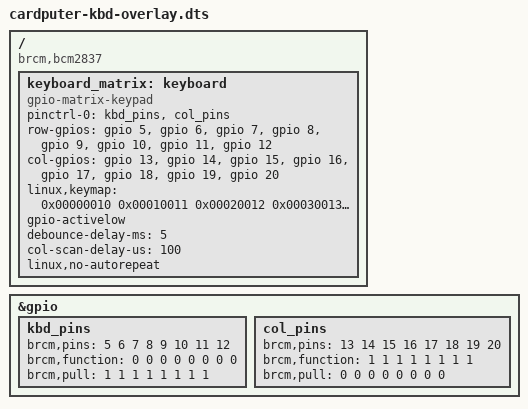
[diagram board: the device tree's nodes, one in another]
// Cardputer Zero 46-Key Matrix Keyboard Overlay
// NOTE: GPIO pin assignments are PLACEHOLDERS pending M5Stack pinout
/dts-v1/;
/plugin/;

/ {
    compatible = "brcm,bcm2837";

    fragment@0 {
        target = <&gpio>;
        __overlay__ {
            kbd_pins: kbd_pins {
                brcm,pins = <5 6 7 8 9 10 11 12>;  // PLACEHOLDER: row pins
                brcm,function = <0 0 0 0 0 0 0 0>; // input
                brcm,pull = <1 1 1 1 1 1 1 1>;     // pull-up
            };
            col_pins: col_pins {
                brcm,pins = <13 14 15 16 17 18 19 20>; // PLACEHOLDER: col pins
                brcm,function = <1 1 1 1 1 1 1 1>;     // output
                brcm,pull = <0 0 0 0 0 0 0 0>;         // no pull
            };
        };
    };

    fragment@1 {
        target-path = "/";
        __overlay__ {
            keyboard_matrix: keyboard {
                compatible = "gpio-matrix-keypad";
                pinctrl-names = "default";
                pinctrl-0 = <&kbd_pins &col_pins>;
                row-gpios = <&gpio 5 0 &gpio 6 0 &gpio 7 0 &gpio 8 0
                             &gpio 9 0 &gpio 10 0 &gpio 11 0 &gpio 12 0>;
                col-gpios = <&gpio 13 0 &gpio 14 0 &gpio 15 0 &gpio 16 0
                             &gpio 17 0 &gpio 18 0 &gpio 19 0 &gpio 20 0>;
                // linux,keymap: raw 32-bit values (row<<24 | col<<16 | key_code)
                // KEY_Q=16 KEY_W=17 KEY_E=18 KEY_R=19 KEY_T=20 KEY_Y=21 KEY_U=22 KEY_I=23
                // KEY_A=30 KEY_S=31 KEY_D=32 KEY_F=33 KEY_G=34 KEY_H=35 KEY_J=36 KEY_K=37
                // KEY_Z=44 KEY_X=45 KEY_C=46 KEY_V=47 KEY_B=48 KEY_N=49 KEY_M=50 KEY_COMMA=51
                // KEY_1=2 KEY_2=3 KEY_3=4 KEY_4=5 KEY_5=6 KEY_6=7 KEY_7=8 KEY_8=9
                // KEY_9=10 KEY_0=11 KEY_ENTER=28 KEY_BACKSPACE=14
                // KEY_TAB=15 KEY_SPACE=57 KEY_LEFTALT=56 KEY_LEFTSHIFT=42
                // KEY_LEFT=105 KEY_RIGHT=106 KEY_DOWN=108 KEY_UP=103
                // KEY_ESC=1 KEY_P=25 KEY_O=24 KEY_L=38
                linux,keymap = <
                    /* Row 0 */          0x00000010 0x00010011 0x00020012 0x00030013
                                        0x00040014 0x00050015 0x00060016 0x00070017
                    /* Row 1 */          0x0000001e 0x0001001f 0x00020020 0x00030021
                                        0x00040022 0x00050023 0x00060024 0x00070025
                    /* Row 2 */          0x0000002c 0x0001002d 0x0002002e 0x0003002f
                                        0x00040030 0x00050031 0x00060032 0x00070033
                    /* Row 3 */          0x00000002 0x00010003 0x00020004 0x00030005
                                        0x00040006 0x00050007 0x00060008 0x00070009
                    /* Row 4 */          0x0000000a 0x0001000b 0x0002001c 0x0003000e
                                        0x0004000f 0x00050039 0x00060038 0x0007002a
                    /* Row 5 */          0x00000069 0x0001006a 0x0002006c 0x00030067
                                        0x00040001 0x00050019 0x00060018 0x00070026
                >;
                gpio-activelow;
                debounce-delay-ms = <5>;
                col-scan-delay-us = <100>;
                linux,no-autorepeat;
            };
        };
    };
};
